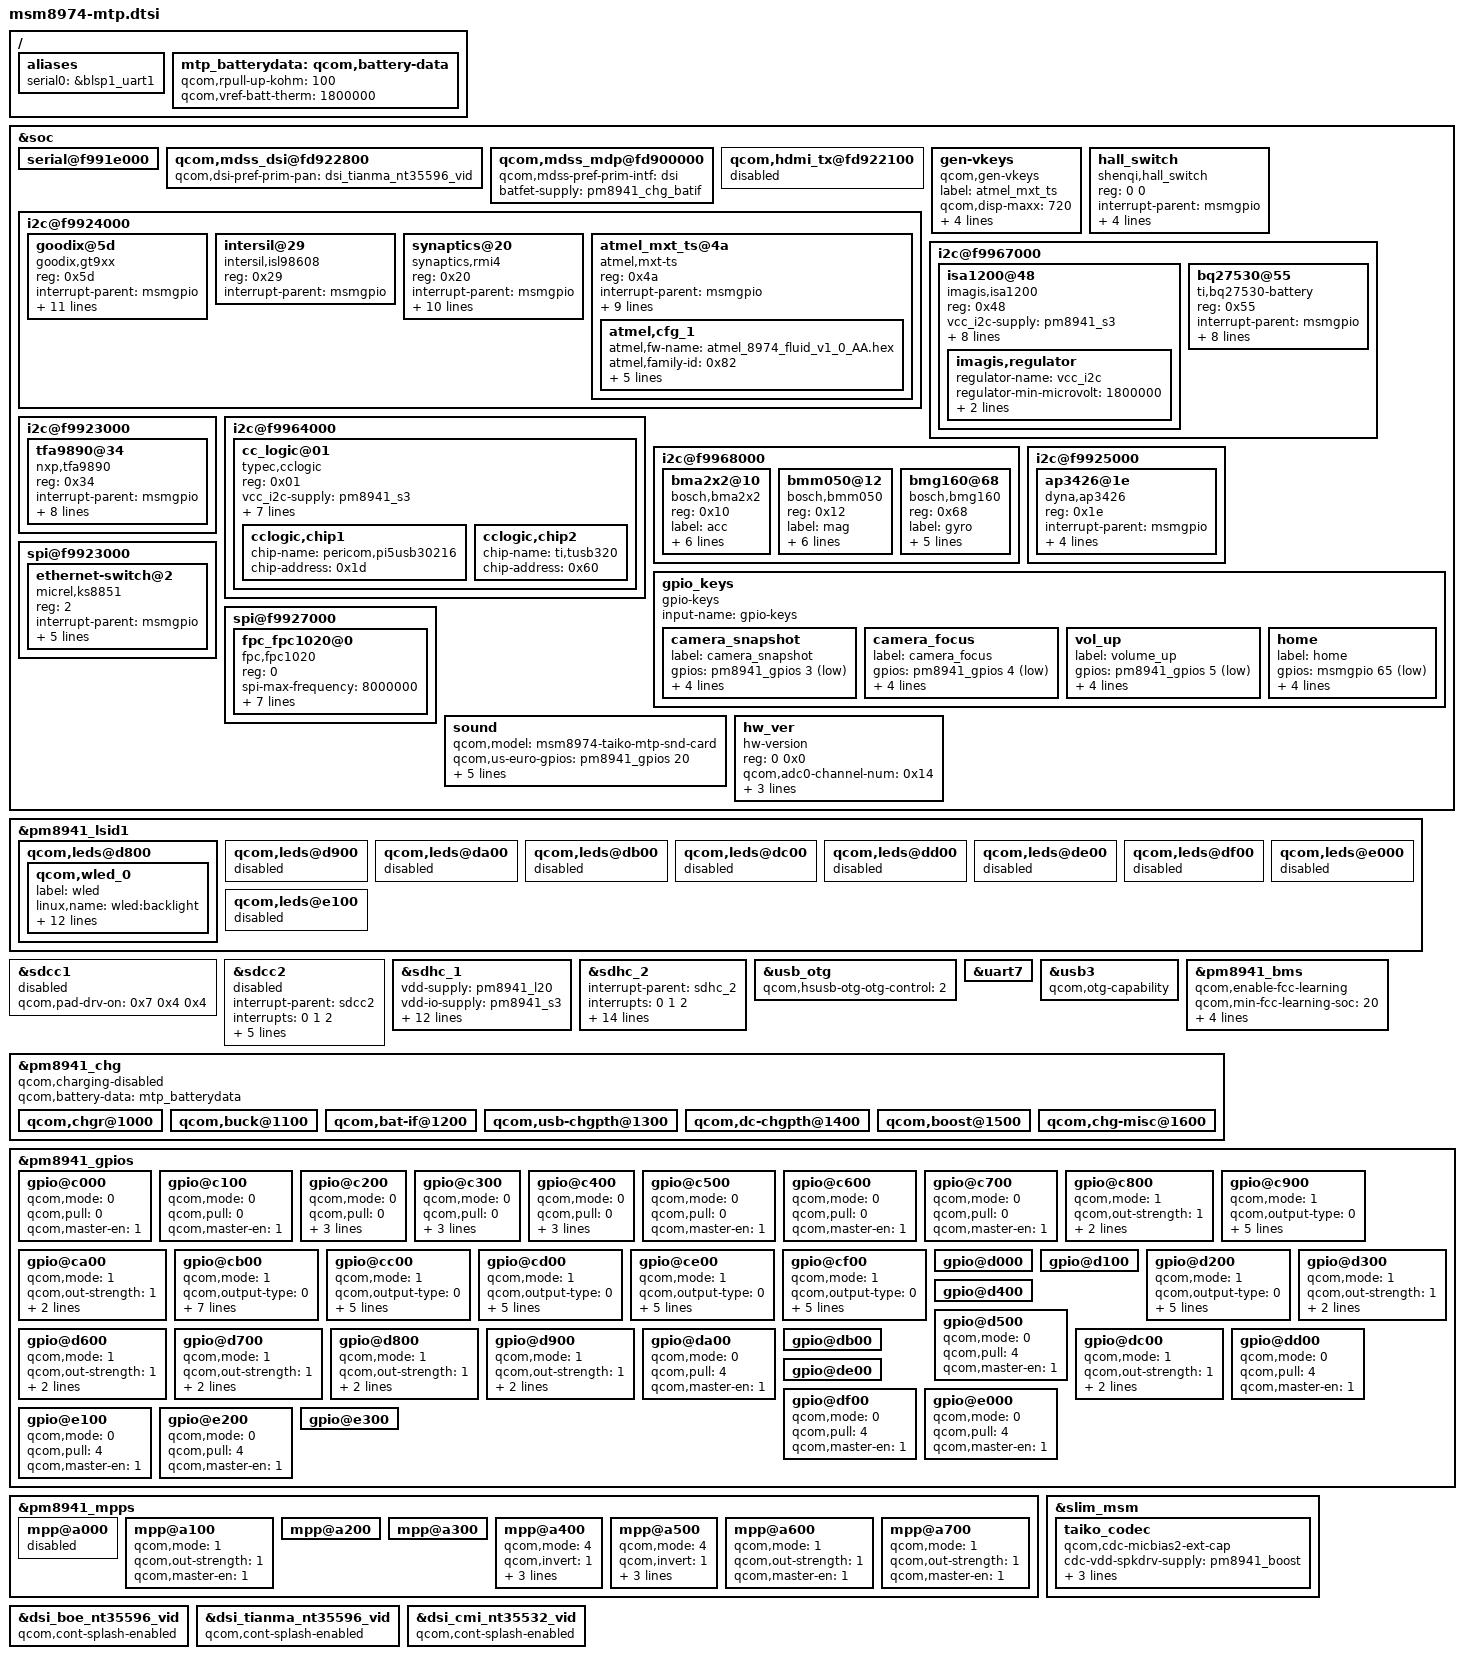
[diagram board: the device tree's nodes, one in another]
/* Copyright (c) 2012-2014, The Linux Foundation. All rights reserved.
 *
 * This program is free software; you can redistribute it and/or modify
 * it under the terms of the GNU General Public License version 2 and
 * only version 2 as published by the Free Software Foundation.
 *
 * This program is distributed in the hope that it will be useful,
 * but WITHOUT ANY WARRANTY; without even the implied warranty of
 * MERCHANTABILITY or FITNESS FOR A PARTICULAR PURPOSE.  See the
 * GNU General Public License for more details.
 */

/include/ "msm8974-leds.dtsi"
/include/ "msm8974-camera-sensor-mtp.dtsi"
/include/ "msm8974-regulator.dtsi"

/ {
	aliases {
		serial0 = &blsp1_uart1;
	};
};

&soc {
	serial@f991e000 {
		status = "ok";
	};

	qcom,mdss_dsi@fd922800 {
		qcom,dsi-pref-prim-pan = <&dsi_tianma_nt35596_vid>;
//		qcom,dsi-pref-prim-pan = <&dsi_cmi_nt35596_vid>;
	};	

	//qcom,mdss_dsi@fd922e00 {
	//	qcom,dsi-pref-prim-pan = <&dsi_lgd_r63319_WQHD_vid1>;
	//};	

	qcom,mdss_mdp@fd900000 {
		qcom,mdss-pref-prim-intf = "dsi";
		batfet-supply = <&pm8941_chg_batif>;
	};

	qcom,hdmi_tx@fd922100 {
		status = "disabled";
	};

	i2c@f9924000 {
		goodix@5d {
			compatible = "goodix,gt9xx";
			reg = <0x5d>;
			interrupt-parent = <&msmgpio>;
			interrupts = <82 0x02>;
			vdd-supply = <&pm8941_l22>;
			vcc_i2c-supply = <&pm8941_lvs1>;
			/* pins used by touchscreen */
			//pinctrl-names = "pmx_ts_active","pmx_ts_suspend";
			//pinctrl-0 = <&ts_int_active &ts_reset_active>;
			//pinctrl-1 = <&ts_int_suspend &ts_reset_suspend>;
			goodix,reset-gpio = <&msmgpio 94 0x0>;
			goodix,irq-gpio = <&msmgpio 82 0x0>;
			//goodix,ldo-en-gpio = <&msmgpio 15 0x00>;
			goodix,panel-coords = <0 0 720 1280>;
			goodix,display-coords = <0 0 720 1280>;
			goodix,button-map= <158 172 139>;
			goodix,family-id = <0x0>;
			goodix,cfg-data = [
		41 1C 02 C0 03 05 31 07 03 08
		14 08 41 32 03 04 00 00 00 00
		00 00 00 18 1A 1E 14 8B 2B 0C
		1C 1E 8C 20 00 00 00 9A 03 2D
		00 00 00 00 00 00 00 00 00 22
		00 4B FA 94 85 02 05 00 00 E5
		1B 1A ED 1C 1C 3C 1F 1E 3C 1F
		24 08 27 1F 00 00 10 38 58 00
		67 60 45 FF FF 07 00 00 00 00
		00 01 06 14 0C 16 E8 03 02 00
		00 03 28 28 E5 00 23 23 00 00
		00 00 02 04 06 08 0A 0C 0E 10
		12 14 16 18 FF FF FF FF FF FF
		FF FF FF FF FF FF FF FF FF FF
		FF FF 00 02 04 06 08 0A 0C 0F
		10 12 13 16 18 1C 1D 1E 1F 20
		21 22 24 26 FF FF FF FF FF FF
		FF FF FF FF FF FF FF FF FF FF
		FF FF FF FF 90 01];
		};

		intersil@29 {
			compatible = "intersil,isl98608";
			reg = <0x29>;
			interrupt-parent = <&msmgpio>;
			//interrupts = <82 0x02>;
			//vcc_i2c-supply = <&pm8941_lvs1>;
			//intersil,reset-gpio = <&msmgpio 94 0x0>;
			//intersil_i2c,irq-gpio = <&msmgpio 82 0x0>;
                };

		synaptics@20 {
			compatible = "synaptics,rmi4";
			reg = <0x20>;
			interrupt-parent = <&msmgpio>;
			interrupts = <61 0x2008>;
			vdd-supply = <&pm8941_l18>;
			vcc_i2c-supply = <&pm8941_lvs1>;
			synaptics,reset-gpio = <&msmgpio 60 0x00>;
			synaptics,irq-gpio = <&msmgpio 61 0x2008>;
			synaptics,display-coords = <0 0 1079 1919>;
			synaptics,i2c-pull-up;
			synaptics,power-down;
			synaptics,disable-gpios;
			synaptics,do-lockdown;
		};

		atmel_mxt_ts@4a {
			compatible = "atmel,mxt-ts";
			reg = <0x4a>;
			interrupt-parent = <&msmgpio>;
			interrupts = <61 0x2>;
			vdd_ana-supply = <&pm8941_l18>;
			vcc_i2c-supply = <&pm8941_lvs1>;
			atmel,reset-gpio = <&msmgpio 60 0x00>;
			atmel,irq-gpio = <&msmgpio 61 0x00>;
			atmel,panel-coords = <0  0 760 1424>;
			atmel,display-coords = <0 0 720 1280>;
			atmel,i2c-pull-up;
			atmel,no-force-update;
			atmel,cfg_1 {
				atmel,fw-name = "atmel_8974_fluid_v1_0_AA.hex";
				atmel,family-id = <0x82>;
				atmel,variant-id = <0x19>;
				atmel,version = <0x10>;
				atmel,build = <0xaa>;
				atmel,config = [
					/* Object 6, Instance = 0 */
					00 00 00 00 00 00
					/* Object 38, Instance = 0 */
					15 01 00 03 0A 0C 00 00
					/* Object 7, Instance = 0 */
					20 08 32 03
					/* Object 8, Instance = 0 */
					0F 00 0A 0A 00 00 0A 0A 00 00
					/* Object 9, Instance = 0 */
					83 00 00 18 0E 00 70 46 02 01
					00 0A 03 31 04 05 0A 0A 90 05
					F8 02 05 F1 F1 0F 00 00 08 2D
					12 06 00 00 00 01
					/* Object 15, Instance = 0 */
					00 00 00 00 00 00 00 00 00 00
					00
					/* Object 18, Instance = 0 */
					00 00
					/* Object 19, Instance = 0 */
					00 00 00 00 00 00
					/* Object 23, Instance = 0 */
					00 00 00 00 00 00 00 00 00 00
					00 00 00 00 00
					/* Object 25, Instance = 0 */
					00 00 00 00 00 00 00 00 00 00
					00 00 00 00 00
					/* Object 40, Instance = 0 */
					00 00 00 00 00
					/* Object 42, Instance = 0 */
					33 1E 19 10 80 00 00 00 FF 00
					/* Object 46, Instance = 0 */
					00 00 10 10 00 00 03 00 00 01
					/* Object 47, Instance = 0 */
					08 0A 28 0A 02 0A 00 8C 00 20
					00 00 00
					/* Object 55, Instance = 0 */
					00 00 00 00 00 00
					/* Object 56, Instance = 0 */
					00 00 00 18 05 05 05 05 05 05
					05 05 05 05 05 05 05 05 05 05
					05 05 05 05 05 05 05 05 00 00
					00 00 00 00 00 00 00 00 00 00
					00 00
					/* Object 57, Instance = 0 */
					00 00 00
					/* Object 61, Instance = 0 */
					00 00 00 00 00
					/* Object 62, Instance = 0 */
					01 2A 00 16 00 00 00 00 0B 01
					02 03 04 08 00 00 08 10 18 05
					00 0A 05 05 50 14 19 34 1A 7F
					00 00 00 00 00 00 00 00 00 30
					05 02 00 01 00 05 00 00 00 00
					00 00 00 00
					];
			};
		};
	};

	gen-vkeys {
		compatible = "qcom,gen-vkeys";
		label = "atmel_mxt_ts";
		qcom,disp-maxx = <720>;
		qcom,disp-maxy = <1280>;
		qcom,panel-maxx = <760>;
		qcom,panel-maxy = <1424>;
		qcom,key-codes = <158 139 102 217>;
	};

    hall_switch {
        reg = <0 0>;
        compatible = "shenqi,hall_switch";
        interrupt-parent = <&msmgpio>;
        interrupts = <80 0>;
        shenqi,hall-irq-gpio = <&msmgpio 80 0x0>;
        vdd-supply = <&pm8941_lvs1>;
        ssc-supply = <&pm8941_l18>;
    };

	i2c@f9967000 {
		isa1200@48 {
			status = "okay";
			reg = <0x48>;
			vcc_i2c-supply = <&pm8941_s3>;
			compatible = "imagis,isa1200";
			label = "vibrator";
			imagis,chip-en;
			imagis,need-pwm-clk;
			imagis,ext-clk-en;
			imagis,hap-en-gpio = <&msmgpio 86 0x00>;
			imagis,max-timeout = <15000>;
			imagis,pwm-div = <256>;
			imagis,mode-ctrl = <2>;
			imagis,regulator {
				regulator-name = "vcc_i2c";
				regulator-min-microvolt = <1800000>;
				regulator-max-microvolt = <1800000>;
				regulator-max-microamp = <9360>;
			};
		};

		bq27530@55 {
			reg = <0x55>;
			compatible = "ti,bq27530-battery";
			interrupt-parent = <&msmgpio>;
			vcc_i2c-supply = <&pm8941_s3>;
			bq27530,chg-int-gpio = <&msmgpio 144 0x00>;
			bq27530,fg-int-gpio = <&msmgpio 86 0x00>;
			bq27530,usb-sw-gpio = <&msmgpio 78 0x00>;
			bq27530,chg-en-gpio = <&pm8941_gpios 10 0x00>;
			bq27530,chg-otg-gpio = <&pm8941_gpios 11 0x00>;
			bq27530,chg-psel-gpio = <&pm8941_gpios 12 0x00>;
			bq27530,usb-sw-en-gpio = <&pm8941_gpios 14 0x00>;
		};
	};

	i2c@f9923000 {
		tfa9890@34 {
			compatible = "nxp,tfa9890";
			reg = <0x34>;
			interrupt-parent = <&msmgpio>;
			interrupts = <46 0x2>;
			irq-gpio = <&msmgpio 46 0x00>;
			reset-gpio = <&msmgpio 0 0x00>;
			reset-gpio-test = <&msmgpio 2 0x00>;
			vdd-supply = <&pm8941_s3>;
			vcc_i2c-supply = <&pm8941_lvs1>;
			tfa9890,i2c-pull-up;
			tfa9890,power-down;
		};
	};

	i2c@f9964000 {
		cc_logic@01 {
			compatible = "typec,cclogic";
			reg = <0x01>;
			vcc_i2c-supply = <&pm8941_s3>;
			interrupt-parent = <&msmgpio>;
			interrupts = <73>;
			cc_logic,irq-gpio = <&msmgpio 73 0x02>; //for 0x8 low_level interrupt, 0x2 falling_edge
			/* cc_logic,function-switch-gpio1 = <&msmgpio 32 0x00>; */
			cc_logic,function-switch-gpio2 = <&msmgpio 31 0x00>;
			cc_logic,usb-ss-gpio = <&msmgpio 53 0x00>;
			/* cc_logic,power-control = <&msmgpio 34 0x00>; */
			cc_logic,i2c-pull-up;

			cclogic,chip1 {
				chip-name = "pericom,pi5usb30216";
				chip-address = <0x1d>;
			};
			cclogic,chip2 {
				chip-name = "ti,tusb320";
				chip-address = <0x60>;
			};
		};
	};

	i2c@f9968000 {
		bma2x2@10 {
			status = "okay";
			reg = <0x10>;
			compatible = "bosch,bma2x2";
			label = "acc";
			interrupt-parent = <&msmgpio>;
			interrupts = <79>;
			vdd-supply = <&pm8941_l18>;
			vcc_i2c-supply = <&pm8941_lvs1>;
			bma2x2,drdy-gpio = <&msmgpio 79 0x00>;
			bma2x2,irq-gpio = <&msmgpio 67 0x00>;
		};

		bmm050@12 {
			status = "okay";
			reg = <0x12>;
			compatible = "bosch,bmm050";
			label = "mag";
			interrupt-parent = <&msmgpio>;
			interrupts = <79>;
			vdd-supply = <&pm8941_l18>;
			vcc_i2c-supply = <&pm8941_lvs1>;
			bmm050,drdy-gpio = <&msmgpio 79 0x00>;
			bmm050,irq-gpio = <&msmgpio 67 0x00>;
		};

		bmg160@68 {
			status = "okay";
			reg = <0x68>;
			compatible = "bosch,bmg160";
			label = "gyro";
			interrupt-parent = <&msmgpio>;
			interrupts = <66>;
			vdd-supply = <&pm8941_l18>;
			vcc_i2c-supply = <&pm8941_lvs1>;
			bmg160,irq-gpio = <&msmgpio 66 0x00>;
		};
	};

	i2c@f9925000 {
		ap3426@1e {
			compatible = "dyna,ap3426";
			reg = <0x1e>;
			interrupt-parent = <&msmgpio>;
			interrupts = <68 0x2>;
			irq-gpio = <&msmgpio 68 0x00>;
			vdd-supply = <&pm8941_l18>;
			vcc_i2c-supply = <&pm8941_lvs1>;
		};
	};

	gpio_keys {
		compatible = "gpio-keys";
		input-name = "gpio-keys";

		camera_snapshot {
			label = "camera_snapshot";
			gpios = <&pm8941_gpios 3 0x1>;
			linux,input-type = <1>;
			linux,code = <0x2fe>;
			gpio-key,wakeup;
			debounce-interval = <15>;
		};

		camera_focus {
			label = "camera_focus";
			gpios = <&pm8941_gpios 4 0x1>;
			linux,input-type = <1>;
			linux,code = <0x210>;
			gpio-key,wakeup;
			debounce-interval = <15>;
		};

		vol_up {
			label = "volume_up";
			gpios = <&pm8941_gpios 5 0x1>;
			linux,input-type = <1>;
			linux,code = <115>;
			gpio-key,wakeup;
			debounce-interval = <15>;
		};

		home {
			label = "home";
			gpios = <&msmgpio 65 0x1>;
			linux,input-type = <1>;
			linux,code = <102>;
			gpio-key,wakeup;
			debounce-interval = <15>;
		};
	};

	spi@f9923000 {
		ethernet-switch@2 {
			compatible = "micrel,ks8851";
			reg = <2>;
			interrupt-parent = <&msmgpio>;
			interrupts = <94 0>;
			spi-max-frequency = <4800000>;
			rst-gpio = <&pm8941_mpps 6 0>;
			vdd-io-supply = <&spi_eth_vreg>;
			vdd-phy-supply = <&spi_eth_vreg>;
		};
	};

	spi@f9927000 {
		fpc_fpc1020@0 {
			compatible = "fpc,fpc1020";
			reg = <0>;
			spi-max-frequency = <8000000>;
			interrupt-parent = <&msmgpio>;
			interrupts = <74 0x1>;
			fpc,gpio_irq  = <74>;
			fpc,gpio_reset = <33>;
			fpc,gpio_cs  = <25>;
                        /* fpc,vddtx_mv = <3300>;  */
                        /* fpc,txout_boost_enable; */
                        /* fpc,force_hwid = <0x1234> */
			/*vcc_spi-supply = <&pm8941_s3>;*/
			vdd_ana-supply = <&spi_eth_vreg>;
			vdd_io-supply = <&spi_eth_vreg>;
		};
	};

	sound {
		qcom,model = "msm8974-taiko-mtp-snd-card";
		qcom,us-euro-gpios = <&pm8941_gpios 20 0>;
		//qcom,usb2_sw_en1 = <&msmgpio 32 0>;
		//qcom,usb2_sw_en2= <&msmgpio 31 0>;
		qcom,audio_r_cmd_sw= <&msmgpio 55 0>;
		qcom,audio_mic_cmd_sw= <&msmgpio 57 0>;
		qcom,anc_audio_cmd= <&msmgpio 89 0>;
		qcom,cdc-micbias2-headset-only;
		qcom,mbhc-audio-jack-type = "4-pole-jack";
	};

    hw_ver {
        reg = <0 0x0>;
        compatible = "hw-version";
        qcom,adc0-channel-num = <0x14>; /* VER_ADC0 */
        qcom,adc1-channel-num = <0x15>; /* VER_ADC1 */
        qcom,hw_ver-vadc = <&pm8941_vadc>;
        gpios = <&msmgpio 56 0>, /* VER_GPIO0 */
              <&msmgpio 92 0>;   /* VER_GPIO1 */
    };
};

//yangjq, 20140422, Disable unused WLED module to save about 3mA current, START
///*
&pm8941_lsid1 {
	qcom,leds@d800 {
		status = "okay";
		qcom,wled_0 {
			label = "wled";
			linux,name = "wled:backlight";
			linux,default-trigger = "bkl-trigger";
			qcom,cs-out-en;
			qcom,op-fdbck = <1>;
			qcom,default-state = "on";
			qcom,max-current = <25>;
			qcom,ctrl-delay-us = <0>;
			qcom,boost-curr-lim = <5>;
			qcom,cp-sel = <0>;
			qcom,switch-freq = <11>;
			qcom,ovp-val = <2>;
			qcom,num-strings = <3>;
			qcom,id = <0>;
		};
	};

	qcom,leds@d900 {
		status = "disabled";
	};

	qcom,leds@da00 {
		status = "disabled";
	};

	qcom,leds@db00 {
		status = "disabled";
	};

	qcom,leds@dc00 {
		status = "disabled";
	};

	qcom,leds@dd00 {
		status = "disabled";
	};

	qcom,leds@de00 {
		status = "disabled";
	};

	qcom,leds@df00 {
		status = "disabled";
	};

	qcom,leds@e000 {
		status = "disabled";
	};

	qcom,leds@e100 {
		status = "disabled";
	};
};

&sdcc1 {
       status = "disabled";
};

&sdcc2 {
	#address-cells = <0>;
	interrupt-parent = <&sdcc2>;
	interrupts = <0 1 2>;
	#interrupt-cells = <1>;
	interrupt-map-mask = <0xffffffff>;
	interrupt-map = <0 &intc 0 125 0
			1 &intc 0 220 0
			2 &msmgpio 62 0x3>;
	interrupt-names = "core_irq", "bam_irq", "status_irq";
	cd-gpios = <&msmgpio 62 0x1>;
	status = "disabled";
};

&sdhc_1 {
	vdd-supply = <&pm8941_l20>;
	vdd-io-supply = <&pm8941_s3>;

	qcom,vdd-always-on;
	qcom,vdd-lpm-sup;
	qcom,vdd-voltage-level = <2950000 2950000>;
	qcom,vdd-current-level = <800 500000>;

	qcom,vdd-io-always-on;
	qcom,vdd-io-voltage-level = <1800000 1800000>;
	qcom,vdd-io-current-level = <250 154000>;

	qcom,pad-pull-on = <0x0 0x3 0x3>; /* no-pull, pull-up, pull-up */
	qcom,pad-pull-off = <0x0 0x3 0x3>; /* no-pull, pull-up, pull-up */
	qcom,pad-drv-on = <0x4 0x4 0x4>; /* 10mA, 10mA, 10mA */
	qcom,pad-drv-off = <0x0 0x0 0x0>; /* 2mA, 2mA, 2mA */

	qcom,nonremovable;
	status = "ok";
};

&sdhc_2 {
	#address-cells = <0>;
	interrupt-parent = <&sdhc_2>;
	interrupts = <0 1 2>;
	#interrupt-cells = <1>;
	interrupt-map-mask = <0xffffffff>;
	interrupt-map = <0 &intc 0 125 0
			1 &intc 0 221 0
			2 &msmgpio 62 0x3>;
	interrupt-names = "hc_irq", "pwr_irq", "status_irq";
	cd-gpios = <&msmgpio 62 0x1>;

	vdd-supply = <&pm8941_l21>;
	vdd-io-supply = <&pm8941_l13>;

	qcom,vdd-voltage-level = <2950000 2950000>;
	qcom,vdd-current-level = <9000 800000>;

	qcom,vdd-io-voltage-level = <1800000 2950000>;
	qcom,vdd-io-current-level = <6 22000>;

	qcom,pad-pull-on = <0x0 0x3 0x3>; /* no-pull, pull-up, pull-up */
	qcom,pad-pull-off = <0x0 0x3 0x3>; /* no-pull, pull-up, pull-up */
	qcom,pad-drv-on = <0x4 0x4 0x4>; /* 10mA, 10mA, 10mA */
	qcom,pad-drv-off = <0x0 0x0 0x0>; /* 2mA, 2mA, 2mA */
	status = "ok";
};

/* Drive strength recommendations for clock line from hardware team is 10 mA.
 * But since the driver has been been using the below values from the start
 * without any problems, continue to use those.
 */
&sdcc1 {
	qcom,pad-drv-on = <0x7 0x4 0x4>; /* 16mA, 10mA, 10mA */
};

&sdcc2 {
	qcom,pad-drv-on = <0x7 0x4 0x4>; /* 16mA, 10mA, 10mA */
};

&sdhc_1 {
	qcom,pad-drv-on = <0x7 0x4 0x4>; /* 16mA, 10mA, 10mA */
};

&sdhc_2 {
	qcom,pad-drv-on = <0x7 0x4 0x4>; /* 16mA, 10mA, 10mA */
};

&usb_otg {
	qcom,hsusb-otg-otg-control = <2>;
};

&uart7 {
	status = "ok";
};

&usb3 {
	qcom,otg-capability;
};

/ {
	mtp_batterydata: qcom,battery-data {
		qcom,rpull-up-kohm = <100>;
		qcom,vref-batt-therm = <1800000>;

		/include/ "batterydata-palladium.dtsi"
		/include/ "batterydata-mtp-3000mah.dtsi"
	};
};

&pm8941_bms {
	qcom,enable-fcc-learning;
	qcom,min-fcc-learning-soc = <20>;
	qcom,min-fcc-ocv-pc = <30>;
	qcom,min-fcc-learning-samples = <5>;
	qcom,fcc-resolution = <10>;
	status = "ok";
	qcom,battery-data = <&mtp_batterydata>;
};

&pm8941_chg {
	status = "ok";
	qcom,charging-disabled;
	qcom,battery-data = <&mtp_batterydata>;

	qcom,chgr@1000 {
		status = "ok";
	};

	qcom,buck@1100 {
		status = "ok";
	};

	qcom,bat-if@1200 {
		status = "ok";
	};

	qcom,usb-chgpth@1300 {
		status = "ok";
	};

	qcom,dc-chgpth@1400 {
		status = "ok";
	};

	qcom,boost@1500 {
		status = "ok";
	};

	qcom,chg-misc@1600 {
		status = "ok";
	};
};

&pm8941_gpios {
	gpio@c000 { /* GPIO 1 */
		qcom,mode = <0>;        /* QPNP_PIN_MODE_DIG_IN */
		qcom,pull = <0>;        /* QPNP_PIN_PULL_UP_30  */
		qcom,master-en = <1>;
	};

	gpio@c100 { /* GPIO 2 */
		qcom,mode = <0>;        /* QPNP_PIN_MODE_DIG_IN */
		qcom,pull = <0>;        /* QPNP_PIN_PULL_UP_30  */
		qcom,master-en = <1>;
	};

	gpio@c200 { /* GPIO 3 */
		qcom,mode = <0>;        /* QPNP_PIN_MODE_DIG_IN */
		qcom,pull = <0>;        /* QPNP_PIN_PULL_UP_30  */
		qcom,vin-sel = <2>;
		qcom,src-sel = <0>;	/* QPNP_PIN_SEL_FUNC_CONSTANT */
		qcom,master-en = <1>;
	};

	gpio@c300 { /* GPIO 4 */
		qcom,mode = <0>;        /* QPNP_PIN_MODE_DIG_IN */
		qcom,pull = <0>;        /* QPNP_PIN_PULL_UP_30  */
		qcom,vin-sel = <2>;     /* QPNP_PIN_VIN2  */
		qcom,src-sel = <0>;	/* QPNP_PIN_SEL_FUNC_CONSTANT */
		qcom,master-en = <1>;
	};

	gpio@c400 { /* GPIO 5 */
		qcom,mode = <0>;        /* QPNP_PIN_MODE_DIG_IN */
		qcom,pull = <0>;        /* QPNP_PIN_PULL_UP_30  */
		qcom,vin-sel = <2>;     /* QPNP_PIN_VIN2  */
		qcom,src-sel = <0>;	/* QPNP_PIN_SEL_FUNC_CONSTANT */
		qcom,master-en = <1>;
	};

	gpio@c500 { /* GPIO 6 */
		qcom,mode = <0>;        /* QPNP_PIN_MODE_DIG_IN */
		qcom,pull = <0>;        /* QPNP_PIN_PULL_UP_30  */
		qcom,master-en = <1>;
	};

	gpio@c600 { /* GPIO 7 */
		qcom,mode = <0>;        /* QPNP_PIN_MODE_DIG_IN */
		qcom,pull = <0>;        /* QPNP_PIN_PULL_UP_30  */
		qcom,master-en = <1>;
	};

	gpio@c700 { /* GPIO 8 */
		qcom,mode = <0>;        /* QPNP_PIN_MODE_DIG_IN */
		qcom,pull = <0>;        /* QPNP_PIN_PULL_UP_30  */
		qcom,master-en = <1>;
	};

	gpio@c800 { /* GPIO 9 */
		qcom,mode = <1>;          /* QPNP_PIN_MODE_DIG_OUT */
		qcom,out-strength = <1>;  /* QPNP_PIN_OUT_STRENGTH_LOW */
		qcom,src-sel = <2>;       /* QPNP_PIN_SEL_FUNC_1  */
		qcom,master-en = <1>;
	};

	gpio@c900 { /* GPIO 10 */
        /*BQ27530_EN*/
		qcom,mode = <1>;          /* QPNP_PIN_MODE_DIG_OUT */
		qcom,output-type = <0>;	  /* CMOS */
		qcom,pull = <5>;		  /* PULL_NO */
		#qcom,out-strength = <2>;  /* QPNP_PIN_OUT_STRENGTH_MED */
		qcom,out-strength = <1>;  /* QPNP_PIN_OUT_STRENGTH_LOW */
		qcom,src-sel = <0>;       /* QPNP_PIN_SEL_FUN_CONSTANT  */
		qcom,master-en = <1>;
	};

	gpio@ca00 { /* GPIO 11 */
		qcom,mode = <1>;          /* QPNP_PIN_MODE_DIG_OUT */
		qcom,out-strength = <1>;  /* QPNP_PIN_OUT_STRENGTH_LOW */
		qcom,src-sel = <0>;       /* QPNP_PIN_SEL_FUNC_  */
		qcom,master-en = <1>;
	};

	gpio@cb00 { /* GPIO 12 */
		qcom,mode = <1>;          /* QPNP_PIN_MODE_DIG_OUT */
		qcom,output-type = <0>;	  /* CMOS */
		#qcom,out-strength = <2>;  /* QPNP_PIN_OUT_STRENGTH_MED */
		qcom,src-sel = <0>;       /* QPNP_PIN_SEL_FUN_CONSTANT  */
		qcom,vin-sel = <0>;     /* QPNP_PIN_VIN2  */
		qcom,pull = <5>;		  /* PULL_NO */
		#qcom,src-sel = <2>;       /* QPNP_PIN_SEL_FUNC_1  */
		qcom,out-strength = <1>;  /* QPNP_PIN_OUT_STRENGTH_LOW */
		qcom,master-en = <1>;
	};

	gpio@cc00 { /* GPIO 13 */
		qcom,mode = <1>;          /* QPNP_PIN_MODE_DIG_OUT */
		qcom,output-type = <0>;
		qcom,pull = <5>;
		qcom,vin-sel = <3>;
		qcom,out-strength = <1>;  /* QPNP_PIN_OUT_STRENGTH_LOW */
		qcom,src-sel = <0>;       /* function: output 1*/ 
		qcom,master-en = <1>;
	};

	gpio@cd00 { /* GPIO 14 */
		qcom,mode = <1>;          /* QPNP_PIN_MODE_DIG_OUT */
		qcom,output-type = <0>;	  /* CMOS */
		qcom,out-strength = <1>;  /* QPNP_PIN_OUT_STRENGTH_LOW */
		#qcom,src-sel = <2>;       /* QPNP_PIN_SEL_FUNC_1  */
		qcom,src-sel = <0>;       /* QPNP_PIN_SEL_FUN_CONSTANT  */
		qcom,vin-sel = <0>;     /* QPNP_PIN_VIN2  */
		qcom,master-en = <1>;
	};

	gpio@ce00 { /* GPIO 15 */
		qcom,mode = <1>;
		qcom,output-type = <0>;
		qcom,pull = <5>;
		qcom,vin-sel = <2>;
		qcom,out-strength = <1>;
		qcom,src-sel = <2>;
		qcom,master-en = <1>;
	};

	gpio@cf00 { /* GPIO 16 */
		qcom,mode = <1>;
		qcom,output-type = <0>;
		qcom,pull = <5>;
		qcom,vin-sel = <2>;
		qcom,out-strength = <3>;
		qcom,src-sel = <3>;       /* QPNP_PIN_SEL_FUNC_2  */
		qcom,master-en = <1>;
	};

	gpio@d000 { /* GPIO 17 */
	};

	gpio@d100 { /* GPIO 18 */
	};

	gpio@d200 { /* GPIO 19 */
		qcom,mode = <1>;		/* QPNP_PIN_MODE_DIG_OUT */
		qcom,output-type = <0>;		/* QPNP_PIN_OUT_BUF_CMOS */
		qcom,pull = <5>;		/* QPNP_PIN_PULL_NO */
		qcom,vin-sel = <2>;		/* QPNP_PIN_VIN2 */
		qcom,out-strength = <1>;	/* QPNP_PIN_OUT_STRENGTH_LOW */
		qcom,src-sel = <0>;		/* QPNP_PIN_SEL_FUNC_CONSTANT */
		qcom,master-en = <1>;
	};

	gpio@d300 { /* GPIO 20 */
		qcom,mode = <1>;          /* QPNP_PIN_MODE_DIG_OUT */
		qcom,out-strength = <1>;  /* QPNP_PIN_OUT_STRENGTH_LOW */
		qcom,src-sel = <2>;       /* QPNP_PIN_SEL_FUNC_1  */
		qcom,master-en = <1>;
	};

	gpio@d400 { /* GPIO 21 */
	};

	gpio@d500 { /* GPIO 22 */
		qcom,mode = <0>;        /* QPNP_PIN_MODE_DIG_IN */
		qcom,pull = <4>;	/* QPNP_PIN_PULL_DN */
		qcom,master-en = <1>;
	};

	gpio@d600 { /* GPIO 23 */
		qcom,mode = <1>;          /* QPNP_PIN_MODE_DIG_OUT */
		qcom,out-strength = <1>;  /* QPNP_PIN_OUT_STRENGTH_LOW */
		qcom,src-sel = <2>;       /* QPNP_PIN_SEL_FUNC_1  */
		qcom,master-en = <1>;
	};

	gpio@d700 { /* GPIO 24 */
		qcom,mode = <1>;          /* QPNP_PIN_MODE_DIG_OUT */
		qcom,out-strength = <1>;  /* QPNP_PIN_OUT_STRENGTH_LOW */
		qcom,src-sel = <2>;       /* QPNP_PIN_SEL_FUNC_1  */
		qcom,master-en = <1>;
	};

	gpio@d800 { /* GPIO 25 */
		qcom,mode = <1>;          /* QPNP_PIN_MODE_DIG_OUT */
		qcom,out-strength = <1>;  /* QPNP_PIN_OUT_STRENGTH_LOW */
		qcom,src-sel = <2>;       /* QPNP_PIN_SEL_FUNC_1  */
		qcom,master-en = <1>;
	};

	gpio@d900 { /* GPIO 26 */
		qcom,mode = <1>;          /* QPNP_PIN_MODE_DIG_OUT */
		qcom,out-strength = <1>;  /* QPNP_PIN_OUT_STRENGTH_LOW */
		qcom,src-sel = <2>;       /* QPNP_PIN_SEL_FUNC_1  */
		qcom,master-en = <1>;
	};

	gpio@da00 { /* GPIO 27 */
		qcom,mode = <0>;        /* QPNP_PIN_MODE_DIG_IN */
		qcom,pull = <4>;	/* QPNP_PIN_PULL_DN */
		qcom,master-en = <1>;
	};

	gpio@db00 { /* GPIO 28 */
	};

	gpio@dc00 { /* GPIO 29 */
		qcom,mode = <1>;          /* QPNP_PIN_MODE_DIG_OUT */
		qcom,out-strength = <1>;  /* QPNP_PIN_OUT_STRENGTH_LOW */
		qcom,src-sel = <2>;       /* QPNP_PIN_SEL_FUNC_1  */
		qcom,master-en = <1>;
	};

	gpio@dd00 { /* GPIO 30 */
		qcom,mode = <0>;        /* QPNP_PIN_MODE_DIG_IN */
		qcom,pull = <4>;	/* QPNP_PIN_PULL_DN */
		qcom,master-en = <1>;
	};

	gpio@de00 { /* GPIO 31 */
	};

	gpio@df00 { /* GPIO 32 */
		qcom,mode = <0>;        /* QPNP_PIN_MODE_DIG_IN */
		qcom,pull = <4>;	/* QPNP_PIN_PULL_DN */
		qcom,master-en = <1>;
	};

	gpio@e000 { /* GPIO 33 */
		qcom,mode = <0>;        /* QPNP_PIN_MODE_DIG_IN */
		qcom,pull = <4>;	/* QPNP_PIN_PULL_DN */
		qcom,master-en = <1>;
	};

	gpio@e100 { /* GPIO 34 */
		qcom,mode = <0>;        /* QPNP_PIN_MODE_DIG_IN */
		qcom,pull = <4>;	/* QPNP_PIN_PULL_DN */
		qcom,master-en = <1>;
	};

	gpio@e200 { /* GPIO 35 */
		qcom,mode = <0>;        /* QPNP_PIN_MODE_DIG_IN */
		qcom,pull = <4>;	/* QPNP_PIN_PULL_DN */
		qcom,master-en = <1>;
	};

	gpio@e300 { /* GPIO 36 */
	};
};

&pm8941_mpps {

	mpp@a000 { /* MPP 1 */
		status = "disabled";
	};

	mpp@a100 { /* MPP 2 */
		qcom,mode = <1>;          /* QPNP_PIN_MODE_DIG_OUT */
		qcom,out-strength = <1>;  /* QPNP_PIN_OUT_STRENGTH_LOW */
		qcom,master-en = <1>;
	};

	mpp@a200 { /* MPP 3 */
	};

	mpp@a300 { /* MPP 4 */
	};

	mpp@a400 { /* MPP 5 */
        qcom,mode = <4>;    /* AIN input */
        qcom,invert = <1>;  /* Enable MPP */
        qcom,ain-route = <0>; /* AMUX 5 */
        qcom,master-en = <1>;
        qcom,src-sel = <0>; /* Function constant */
	};

	mpp@a500 { /* MPP 6 */
        qcom,mode = <4>;    /* AIN input */
        qcom,invert = <1>;  /* Enable MPP */
        qcom,ain-route = <1>; /* AMUX 6 */
        qcom,master-en = <1>;
        qcom,src-sel = <0>; /* Function constant */
	};

	mpp@a600 { /* MPP 7 */
		qcom,mode = <1>;          /* QPNP_PIN_MODE_DIG_OUT */
		qcom,out-strength = <1>;  /* QPNP_PIN_OUT_STRENGTH_LOW */
		qcom,master-en = <1>;
	};

	mpp@a700 { /* MPP 8 */
		qcom,mode = <1>;          /* QPNP_PIN_MODE_DIG_OUT */
		qcom,out-strength = <1>;  /* QPNP_PIN_OUT_STRENGTH_LOW */
		qcom,master-en = <1>;
	};
};

&slim_msm {
	taiko_codec {
/*		qcom,cdc-micbias1-ext-cap;*/
		qcom,cdc-micbias2-ext-cap;
/*		qcom,cdc-micbias3-ext-cap;*/
/*		qcom,cdc-micbias4-ext-cap;*/

		cdc-vdd-spkdrv-supply = <&pm8941_boost>;
		qcom,cdc-vdd-spkdrv-voltage = <5000000 5000000>;
		qcom,cdc-vdd-spkdrv-current = <1250000>;

		qcom,cdc-on-demand-supplies = "cdc-vdd-spkdrv";
	};
};
//*/
//yangjq, 20140422, Disable unused WLED module to save about 3mA current, END



&dsi_boe_nt35596_vid {
	qcom,cont-splash-enabled;
};

&dsi_tianma_nt35596_vid {
	qcom,cont-splash-enabled;
};


&dsi_cmi_nt35532_vid {
	qcom,cont-splash-enabled;
};
